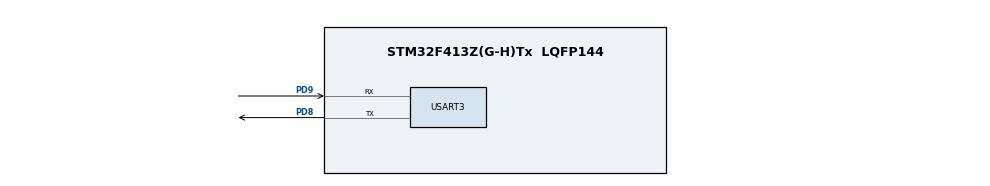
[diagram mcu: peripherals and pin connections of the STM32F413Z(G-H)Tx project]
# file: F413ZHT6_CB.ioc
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Dma.Request0=USART3_RX
Dma.USART3_RX.0.Direction=DMA_PERIPH_TO_MEMORY
Dma.USART3_RX.0.FIFOMode=DMA_FIFOMODE_DISABLE
Dma.USART3_RX.0.Instance=DMA1_Stream1
Dma.USART3_RX.0.MemDataAlignment=DMA_MDATAALIGN_BYTE
Dma.USART3_RX.0.MemInc=DMA_MINC_ENABLE
Dma.USART3_RX.0.Mode=DMA_NORMAL
Dma.USART3_RX.0.PeriphDataAlignment=DMA_PDATAALIGN_BYTE
Dma.USART3_RX.0.PeriphInc=DMA_PINC_DISABLE
Dma.USART3_RX.0.Priority=DMA_PRIORITY_LOW
FREERTOS.Tasks01=defaultTask,-3,128,StartDefaultTask,Default,NULL,Dynamic,NULL,NULL;consumerTask,0,128,consumerTaskHook,Default,NULL,Dynamic,NULL,NULL
FREERTOS.configUSE_NEWLIB_REENTRANT=1
Mcu.Family=STM32F4
Mcu.Name=STM32F413Z(G-H)Tx
Mcu.Package=LQFP144
NVIC.DMA1_Stream1_IRQn=true\:5\:0\:false\:false\:true\:true\:false\:true\:true
NVIC.PriorityGroup=NVIC_PRIORITYGROUP_4
NVIC.TIM1_UP_TIM10_IRQn=true\:15\:0\:false\:false\:true\:false\:false\:true\:true
NVIC.TimeBase=TIM1_UP_TIM10_IRQn
NVIC.TimeBaseIP=TIM1
NVIC.USART3_IRQn=true\:5\:0\:false\:false\:true\:true\:true\:true\:true
PD8.Mode=Asynchronous
PD8.Signal=USART3_TX
PD9.Mode=Asynchronous
PD9.Signal=USART3_RX
PH0\ -\ OSC_IN.Mode=HSE-External-Oscillator
PH0\ -\ OSC_IN.Signal=RCC_OSC_IN
PH1\ -\ OSC_OUT.Mode=HSE-External-Oscillator
PH1\ -\ OSC_OUT.Signal=RCC_OSC_OUT
ProjectManager.HeapSize=0x200
ProjectManager.StackSize=0x400
ProjectManager.TargetToolchain=STM32CubeIDE
RCC.CortexFreq_Value=16000000
RCC.USBFreq_Value=96000000
RCC.VCOOutputFreq_Value=192000000
USART3.VirtualMode=VM_ASYNC
VP_FREERTOS_VS_CMSIS_V1.Mode=CMSIS_V1
VP_SYS_VS_tim1.Mode=TIM1
board=custom

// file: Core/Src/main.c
/* USER CODE BEGIN Header */
/**
  ******************************************************************************
  * @file           : main.c
  * @brief          : Main program body
  ******************************************************************************
  * @attention
  *
  * Copyright (c) 2022 STMicroelectronics.
  * All rights reserved.
  *
  * This software is licensed under terms that can be found in the LICENSE file
  * in the root directory of this software component.
  * If no LICENSE file comes with this software, it is provided AS-IS.
  *
  ******************************************************************************
  */
/* USER CODE END Header */
#include "main.h"
#include "cmsis_os.h"

/* USER CODE BEGIN Includes */
#include "string.h"  // For memcpy
#include "stdlib.h"  // For abs
/* USER CODE END Includes */

UART_HandleTypeDef huart3;
DMA_HandleTypeDef hdma_usart3_rx;

osThreadId defaultTaskHandle;
osThreadId consumerTaskHandle;

void SystemClock_Config(void);
static void MX_GPIO_Init(void);
static void MX_DMA_Init(void);
static void MX_USART3_UART_Init(void);
void StartDefaultTask(void const * argument);
void consumerTaskHook(void const * argument);

/* USER CODE BEGIN 0 */

/*
 * 1. Assume that an application transmits a large text file in chunks. These chunks are received via
 *    the fixed size UART rx_buffer which will be smaller than the UART circular buffer.
 *    and the size of the application
 */

#define RX_RB_SZ 5
#define RX_RCB_SZ 10
#define RX_RCB_EMPTY 1

// Receive Circular Buffer
typedef struct RecvCBuffer {
	uint8_t rxb[RX_RB_SZ];     // The receive buffer (or message)
	uint8_t rxcb[RX_RCB_SZ];   // The circular buffer
	int16_t head;
	int16_t tail;
} _RXCB_;

/*
 * 2. The receive circular buffer data structure
 */
_RXCB_ rcb = {.tail = -1, .head = -1};

int16_t drop_msgs = 0;
int16_t read_msgs = 0;
/*
 * 3. Declare the rx receive buffer
 */
//uint8_t rx_buffer[RX_BUFFER_SZ];

/* USER CODE END 0 */

int main(void)
{

  /* MCU Configuration--------------------------------------------------------*/

  /* Reset of all peripherals, Initializes the Flash interface and the Systick. */
  HAL_Init();

  /* USER CODE BEGIN Init */
  //rcb.head = -1;
  //rcb.tail = -1;
  /* USER CODE END Init */

  /* Configure the system clock */
  SystemClock_Config();

  /* Initialize all configured peripherals */
  MX_GPIO_Init();
  MX_DMA_Init();
  MX_USART3_UART_Init();
  /* USER CODE BEGIN 2 */
  HAL_UARTEx_ReceiveToIdle_DMA(&huart3, rcb.rxb, RX_RB_SZ);
  __HAL_DMA_DISABLE_IT(&hdma_usart3_rx, DMA_IT_HT);
  /* USER CODE END 2 */

  /* Create the thread(s) */
  /* definition and creation of defaultTask */
  osThreadDef(defaultTask, StartDefaultTask, osPriorityIdle, 0, 128);
  defaultTaskHandle = osThreadCreate(osThread(defaultTask), NULL);

  /* definition and creation of consumerTask */
  osThreadDef(consumerTask, consumerTaskHook, osPriorityNormal, 0, 128);
  consumerTaskHandle = osThreadCreate(osThread(consumerTask), NULL);

  /* Start scheduler */
  osKernelStart();

  /* We should never get here as control is now taken by the scheduler */
  /* Infinite loop */
  while (1)
  {

  }
}

void SystemClock_Config(void)
{
  RCC_OscInitTypeDef RCC_OscInitStruct = {0};
  RCC_ClkInitTypeDef RCC_ClkInitStruct = {0};

  /** Configure the main internal regulator output voltage
  */
  __HAL_RCC_PWR_CLK_ENABLE();
  __HAL_PWR_VOLTAGESCALING_CONFIG(PWR_REGULATOR_VOLTAGE_SCALE1);

  /** Initializes the RCC Oscillators according to the specified parameters
  * in the RCC_OscInitTypeDef structure.
  */
  RCC_OscInitStruct.OscillatorType = RCC_OSCILLATORTYPE_HSI;
  RCC_OscInitStruct.HSIState = RCC_HSI_ON;
  RCC_OscInitStruct.HSICalibrationValue = RCC_HSICALIBRATION_DEFAULT;
  RCC_OscInitStruct.PLL.PLLState = RCC_PLL_NONE;
  if (HAL_RCC_OscConfig(&RCC_OscInitStruct) != HAL_OK)
  {
    Error_Handler();
  }

  /** Initializes the CPU, AHB and APB buses clocks
  */
  RCC_ClkInitStruct.ClockType = RCC_CLOCKTYPE_HCLK|RCC_CLOCKTYPE_SYSCLK
                              |RCC_CLOCKTYPE_PCLK1|RCC_CLOCKTYPE_PCLK2;
  RCC_ClkInitStruct.SYSCLKSource = RCC_SYSCLKSOURCE_HSI;
  RCC_ClkInitStruct.AHBCLKDivider = RCC_SYSCLK_DIV1;
  RCC_ClkInitStruct.APB1CLKDivider = RCC_HCLK_DIV1;
  RCC_ClkInitStruct.APB2CLKDivider = RCC_HCLK_DIV1;

  if (HAL_RCC_ClockConfig(&RCC_ClkInitStruct, FLASH_LATENCY_0) != HAL_OK)
  {
    Error_Handler();
  }
}

static void MX_USART3_UART_Init(void)
{

  huart3.Instance = USART3;
  huart3.Init.BaudRate = 115200;
  huart3.Init.WordLength = UART_WORDLENGTH_8B;
  huart3.Init.StopBits = UART_STOPBITS_1;
  huart3.Init.Parity = UART_PARITY_NONE;
  huart3.Init.Mode = UART_MODE_TX_RX;
  huart3.Init.HwFlowCtl = UART_HWCONTROL_NONE;
  huart3.Init.OverSampling = UART_OVERSAMPLING_16;
  if (HAL_UART_Init(&huart3) != HAL_OK)
  {
    Error_Handler();
  }

}

static void MX_DMA_Init(void)
{

  /* DMA controller clock enable */
  __HAL_RCC_DMA1_CLK_ENABLE();

  /* DMA interrupt init */
  /* DMA1_Stream1_IRQn interrupt configuration */
  HAL_NVIC_SetPriority(DMA1_Stream1_IRQn, 5, 0);
  HAL_NVIC_EnableIRQ(DMA1_Stream1_IRQn);

}

static void MX_GPIO_Init(void)
{

  /* GPIO Ports Clock Enable */
  __HAL_RCC_GPIOH_CLK_ENABLE();
  __HAL_RCC_GPIOD_CLK_ENABLE();

}

/* USER CODE BEGIN 4 */

void HAL_UARTEx_RxEventCallback(UART_HandleTypeDef *huart, uint16_t rxb_sz){

	if( huart->Instance == USART3) {

		// The is space in front of the buffer
		if( rcb.head > rcb.tail  && rxb_sz <= (RX_RCB_SZ - (rcb.head - rcb.tail )) )
		{
			// write at the free locations at the end of the buffer
			int16_t k = ((RX_RCB_SZ - rcb.head) > rxb_sz)? rxb_sz : RX_RCB_SZ - rcb.head;
			memcpy( (uint8_t *) rcb.rxcb + rcb.head, (uint8_t *) rcb.rxb, k );
			if(  (rxb_sz - k) > 0 )
				memcpy( (uint8_t *) rcb.rxcb, (uint8_t *) rcb.rxb + k, (rxb_sz - k) );
			rcb.head = rcb.head + rxb_sz % RX_RCB_SZ;
		}

		// There is space somewhere in the beginning of the buffer
		if( rcb.head < rcb.tail &&  rxb_sz <= (RX_RCB_SZ - abs(rcb.head - rcb.tail )) )
		{
			memcpy( (uint8_t *) rcb.rxcb + rcb.head, (uint8_t *) rcb.rxb, rxb_sz);
			rcb.head = rcb.head + rxb_sz;
		}

		// If the buffer is full or the incoming message does not fit, then it is drop and the
		// pending task is notified
		if( rcb.head == rcb.tail || rxb_sz > (RX_RCB_SZ - abs(rcb.head - rcb.tail )) ) {
			// must signal the consumer task that the buffer is full.
			drop_msgs++;
		}

		// The circular buffer is empty
		if( rcb.tail == -1 && rcb.head == -1) {
			memcpy( (uint8_t *) rcb.rxcb, (uint8_t *) rcb.rxb, rxb_sz);
			rcb.tail = 0;
			rcb.head = rxb_sz;
		}

		// Reset the UART and disable half transfer mode
		HAL_UARTEx_ReceiveToIdle_DMA(&huart3, rcb.rxb, RX_RB_SZ);
		__HAL_DMA_DISABLE_IT(&hdma_usart3_rx, DMA_IT_HT);

	}
}

char poll(uint8_t * rxb, int sz )
{
	// the buffer is empty
	if(rcb.head == rcb.tail)
		return RX_RCB_EMPTY;

	// the buffer has not been initiated
	if(rcb.head == -1 && rcb.tail == -1)
		return RX_RCB_EMPTY;

	// estimate the number of characters in the buffer
	int16_t k = ( rcb.head > rcb.tail )?  rcb.head - rcb.tail : (RX_RCB_SZ - rcb.tail) + rcb.head;

	// elements in the buffer are located at the end of it
	if( rcb.head > rcb.tail )
	{
		memcpy((uint8_t *) rxb, (uint8_t *) rcb.rxcb + rcb.tail, k);
		// no need to reset the buffer, just move the pointers
		rcb.tail = rcb.tail + k;
		// TODO: evaluate if a tailing character must be added to the rxb
	}

	// elements in the buffer are located at the end and at the beginning
	if( rcb.tail > rcb.head )
	{
		// copy elements at the end of the buffer first
		memcpy((uint8_t *) rxb, (uint8_t *) rcb.rxcb + rcb.tail, (RX_RCB_SZ - rcb.tail) );
		// copy elements at the beginning of the second buffer
		memcpy((uint8_t *) rxb + (RX_RCB_SZ - rcb.tail), (uint8_t *) rcb.rxcb, rcb.head );

		// copy the elements at the beginning of the buffer subsequently

	}

	return !RX_RCB_EMPTY;
}

/* USER CODE END 4 */

void StartDefaultTask(void const * argument)
{
  for(;;)
  {
    osDelay(1);
  }
}

void consumerTaskHook(void const * argument)
{
	TickType_t TaskTimeStamp;
	TickType_t DelayTimeMsec = 10000;  // wait 2s then poll

	// We will assume the user gives a finite size buffer (3 characters in this example)
	uint8_t msg[RX_RB_SZ];
	for(;;)
	{
		// wait 2s then try to move data from kernel to user memory space
		osDelayUntil(&TaskTimeStamp, DelayTimeMsec);
		// non-blocking access to the buffer
		if( poll(msg, RX_RB_SZ) == RX_RCB_EMPTY )
			read_msgs++;  // successfully read messages
	}
}

void HAL_TIM_PeriodElapsedCallback(TIM_HandleTypeDef *htim)
{
  if (htim->Instance == TIM1) {
    HAL_IncTick();
  }
}

void Error_Handler(void)
{
  __disable_irq();
  while (1)
  {
  }
}
